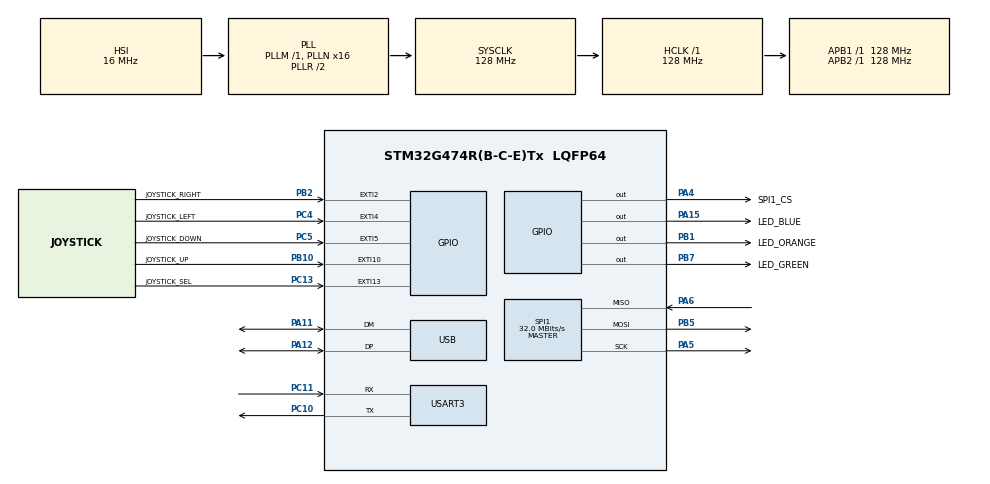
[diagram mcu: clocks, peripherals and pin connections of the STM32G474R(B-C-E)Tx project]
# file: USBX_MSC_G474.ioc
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Mcu.Family=STM32G4
Mcu.Name=STM32G474R(B-C-E)Tx
Mcu.Package=LQFP64
NVIC.PriorityGroup=NVIC_PRIORITYGROUP_4
NVIC.TIM6_DAC_IRQn=true\:15\:0\:false\:false\:true\:false\:false\:true\:true
NVIC.TimeBase=TIM6_DAC_IRQn
NVIC.TimeBaseIP=TIM6
NVIC.USB_LP_IRQn=true\:0\:0\:false\:false\:true\:false\:true\:true\:true
PA11.Mode=Device
PA11.Signal=USB_DM
PA12.Mode=Device
PA12.Signal=USB_DP
PA13.Mode=Trace_Asynchronous_SW
PA13.Signal=SYS_JTMS-SWDIO
PA14.Mode=Trace_Asynchronous_SW
PA14.Signal=SYS_JTCK-SWCLK
PA15.GPIO_Label=LED_BLUE
PA15.Signal=GPIO_Output
PA4.GPIO_Label=SPI1_CS
PA4.GPIO_PuPd=GPIO_PULLUP
PA4.GPIO_Speed=GPIO_SPEED_FREQ_VERY_HIGH
PA4.PinState=GPIO_PIN_SET
PA4.Signal=GPIO_Output
PA5.GPIO_Mode=GPIO_MODE_AF_PP
PA5.GPIO_PuPd=GPIO_PULLDOWN
PA5.GPIO_Speed=GPIO_SPEED_FREQ_VERY_HIGH
PA5.Mode=Full_Duplex_Master
PA5.Signal=SPI1_SCK
PA6.GPIO_Mode=GPIO_MODE_AF_PP
PA6.GPIO_PuPd=GPIO_PULLDOWN
PA6.GPIO_Speed=GPIO_SPEED_FREQ_VERY_HIGH
PA6.Mode=Full_Duplex_Master
PA6.Signal=SPI1_MISO
PA8.GPIO_Label=BUCK_BLUE_DRIVE
PA8.Signal=S_TIM1_CH1
PB1.GPIO_Label=LED_ORANGE
PB1.Signal=GPIO_Output
PB10.GPIO_Label=JOYSTICK_UP
PB10.Signal=GPXTI10
PB2.GPIO_Label=JOYSTICK_RIGHT
PB2.Signal=GPXTI2
PB3.Mode=Trace_Asynchronous_SW
PB3.Signal=SYS_JTDO-SWO
PB5.GPIO_Mode=GPIO_MODE_AF_PP
PB5.GPIO_PuPd=GPIO_PULLDOWN
PB5.GPIO_Speed=GPIO_SPEED_FREQ_VERY_HIGH
PB5.Mode=Full_Duplex_Master
PB5.Signal=SPI1_MOSI
PB7.GPIO_Label=LED_GREEN
PB7.Signal=GPIO_Output
PC10.Mode=Asynchronous
PC10.Signal=USART3_TX
PC11.Mode=Asynchronous
PC11.Signal=USART3_RX
PC13.GPIO_Label=JOYSTICK_SEL
PC13.Signal=GPXTI13
PC4.GPIO_Label=JOYSTICK_LEFT
PC4.Signal=GPXTI4
PC5.GPIO_Label=JOYSTICK_DOWN
PC5.Signal=GPXTI5
PC6.GPIO_Label=BUCK_RED_DRIVE
PC6.Signal=S_TIM3_CH1
PC8.GPIO_Label=BUCK_GREEN_DRIVE
PC8.Signal=S_TIM3_CH3
ProjectManager.HeapSize=0x200
ProjectManager.StackSize=0x400
ProjectManager.TargetToolchain=STM32CubeIDE
RCC.ADC12Freq_Value=128000000
RCC.ADC345Freq_Value=128000000
RCC.AHBFreq_Value=128000000
RCC.APB1Freq_Value=128000000
RCC.APB1TimFreq_Value=128000000
RCC.APB2Freq_Value=128000000
RCC.APB2TimFreq_Value=128000000
RCC.CK48CLockSelection=RCC_USBCLKSOURCE_HSI48
RCC.CortexFreq_Value=128000000
RCC.EXTERNAL_CLOCK_VALUE=12288000
RCC.HCLKFreq_Value=128000000
RCC.HSE_VALUE=8000000
RCC.HSI48_VALUE=48000000
RCC.HSI_VALUE=16000000
RCC.LSE_VALUE=32768
RCC.PLLN=16
RCC.SYSCLKFreq_VALUE=128000000
RCC.SYSCLKSource=RCC_SYSCLKSOURCE_PLLCLK
RCC.USBFreq_Value=48000000
RCC.VCOOutputFreq_Value=256000000
SH.S_TIM1_CH1.0=TIM1_CH1
SH.S_TIM3_CH1.0=TIM3_CH1
SH.S_TIM3_CH3.0=TIM3_CH3
SPI1.BaudRatePrescaler=SPI_BAUDRATEPRESCALER_4
SPI1.CalculateBaudRate=32.0 MBits/s
SPI1.DataSize=SPI_DATASIZE_8BIT
SPI1.Direction=SPI_DIRECTION_2LINES
SPI1.Mode=SPI_MODE_MASTER
SPI1.VirtualType=VM_MASTER
STMicroelectronics.X-CUBE-AZRTOS-G4.2.0.0.ThreadXCcRTOSJjThreadXJjCore=true
STMicroelectronics.X-CUBE-AZRTOS-G4.2.0.0.USBD_MSC_EPOUT_ADDR=1
STMicroelectronics.X-CUBE-AZRTOS-G4.2.0.0.USBXCcUSBJjUSBXJjCoreSystem=true
STMicroelectronics.X-CUBE-AZRTOS-G4.2.0.0.USBXCcUSBJjUSBXJjUXOoDeviceOoClassOoSTORAGE=true
STMicroelectronics.X-CUBE-AZRTOS-G4.2.0.0.USBXCcUSBJjUSBXJjUXOoDeviceOoControllers=true
STMicroelectronics.X-CUBE-AZRTOS-G4.2.0.0.USBXCcUSBJjUSBXJjUXOoDeviceOoCoreStack=true
STMicroelectronics.X-CUBE-AZRTOS-G4.2.0.0.USBX_DEVICE_SYS_SIZE=6*1024
STMicroelectronics.X-CUBE-AZRTOS-G4.2.0.0.UX_DEVICE_APP_MEM_POOL_SIZE=12*1024
STMicroelectronics.X-CUBE-AZRTOS-G4.2.0.0.UX_SLAVE_REQUEST_DATA_MAX_LENGTH=512
STMicroelectronics.X-CUBE-AZRTOS-G4.2.0.0_IsAnAzureRtosMw=true
USART3.VirtualMode-Asynchronous=VM_ASYNC
VP_STMicroelectronics.X-CUBE-AZRTOS-G4_VS_RTOSJjThreadX_6.2.0_2.0.0.Mode=RTOSJjThreadX
VP_STMicroelectronics.X-CUBE-AZRTOS-G4_VS_USBJjUSBX_6.2.0_2.0.0.Mode=USBJjUSBX
VP_SYS_VS_tim6.Mode=TIM6
board=custom

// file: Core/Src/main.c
/* USER CODE BEGIN Header */
/**
  ******************************************************************************
  * @file           : main.c
  * @brief          : Main program body
  ******************************************************************************
  * @attention
  *
  * Copyright (c) 2023 STMicroelectronics.
  * All rights reserved.
  *
  * This software is licensed under terms that can be found in the LICENSE file
  * in the root directory of this software component.
  * If no LICENSE file comes with this software, it is provided AS-IS.
  *
  ******************************************************************************
  */
/* USER CODE END Header */
#include "app_threadx.h"
#include "main.h"
#include "spi.h"
#include "usart.h"
#include "usb.h"
#include "gpio.h"

/* USER CODE BEGIN Includes */
#include "W25Qxx.h"
#include <stdio.h>
/* USER CODE END Includes */

void SystemClock_Config(void);

/* USER CODE BEGIN 0 */
int __io_putchar(int ch)
{
	HAL_UART_Transmit(&huart3, (uint8_t *)&ch, 1, 0xFF);
	return ch;
}
/* USER CODE END 0 */

int main(void)
{

  /* MCU Configuration--------------------------------------------------------*/

  /* Reset of all peripherals, Initializes the Flash interface and the Systick. */
  HAL_Init();

  /* Configure the system clock */
  SystemClock_Config();

  /* Initialize all configured peripherals */
  MX_GPIO_Init();
  MX_SPI1_Init();
  MX_USART3_UART_Init();
  /* USER CODE BEGIN 2 */
  W25qxx_Init();
  /* USER CODE END 2 */

  MX_ThreadX_Init();

  /* We should never get here as control is now taken by the scheduler */
  /* Infinite loop */
  while (1)
  {

  }
}

void SystemClock_Config(void)
{
  RCC_OscInitTypeDef RCC_OscInitStruct = {0};
  RCC_ClkInitTypeDef RCC_ClkInitStruct = {0};

  /** Configure the main internal regulator output voltage
  */
  HAL_PWREx_ControlVoltageScaling(PWR_REGULATOR_VOLTAGE_SCALE1);

  /** Initializes the RCC Oscillators according to the specified parameters
  * in the RCC_OscInitTypeDef structure.
  */
  RCC_OscInitStruct.OscillatorType = RCC_OSCILLATORTYPE_HSI|RCC_OSCILLATORTYPE_HSI48;
  RCC_OscInitStruct.HSIState = RCC_HSI_ON;
  RCC_OscInitStruct.HSICalibrationValue = RCC_HSICALIBRATION_DEFAULT;
  RCC_OscInitStruct.HSI48State = RCC_HSI48_ON;
  RCC_OscInitStruct.PLL.PLLState = RCC_PLL_ON;
  RCC_OscInitStruct.PLL.PLLSource = RCC_PLLSOURCE_HSI;
  RCC_OscInitStruct.PLL.PLLM = RCC_PLLM_DIV1;
  RCC_OscInitStruct.PLL.PLLN = 16;
  RCC_OscInitStruct.PLL.PLLP = RCC_PLLP_DIV2;
  RCC_OscInitStruct.PLL.PLLQ = RCC_PLLQ_DIV2;
  RCC_OscInitStruct.PLL.PLLR = RCC_PLLR_DIV2;
  if (HAL_RCC_OscConfig(&RCC_OscInitStruct) != HAL_OK)
  {
    Error_Handler();
  }

  /** Initializes the CPU, AHB and APB buses clocks
  */
  RCC_ClkInitStruct.ClockType = RCC_CLOCKTYPE_HCLK|RCC_CLOCKTYPE_SYSCLK
                              |RCC_CLOCKTYPE_PCLK1|RCC_CLOCKTYPE_PCLK2;
  RCC_ClkInitStruct.SYSCLKSource = RCC_SYSCLKSOURCE_PLLCLK;
  RCC_ClkInitStruct.AHBCLKDivider = RCC_SYSCLK_DIV1;
  RCC_ClkInitStruct.APB1CLKDivider = RCC_HCLK_DIV1;
  RCC_ClkInitStruct.APB2CLKDivider = RCC_HCLK_DIV1;

  if (HAL_RCC_ClockConfig(&RCC_ClkInitStruct, FLASH_LATENCY_4) != HAL_OK)
  {
    Error_Handler();
  }
}

void HAL_TIM_PeriodElapsedCallback(TIM_HandleTypeDef *htim)
{
  if (htim->Instance == TIM6) {
    HAL_IncTick();
  }
}

void Error_Handler(void)
{
  __disable_irq();
  while (1)
  {
  }
}
